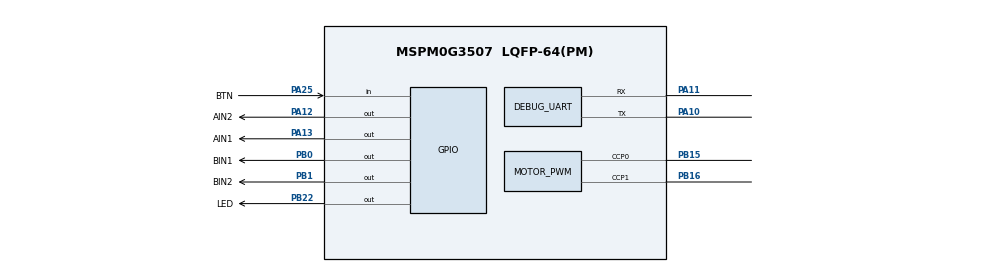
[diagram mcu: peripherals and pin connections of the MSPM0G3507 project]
/**
 * MSPM0G3507 PID Tuner Car
 *
 * PA25: start/stop key, active low
 * UART0: PA10=TX, PA11=RX, 115200 8N1 for PC PID tuner
 * TB6612FNG:
 *   A channel = right wheel: PWMA=PB15/TIMG8_C0, AIN1=PA13, AIN2=PA12
 *   B channel = left wheel:  PWMB=PB16/TIMG8_C1, BIN1=PB0,  BIN2=PB1
 * Encoders:
 *   Right A phase = PA15 edge interrupt
 *   Left  A phase = PA17 edge interrupt
 */
//@cliArgs --device "MSPM0G350X" --package "LQFP-64(PM)" --part "Default"
//@v2CliArgs --device "MSPM0G3507" --package "LQFP-64(PM)"

const GPIO   = scripting.addModule("/ti/driverlib/GPIO", {}, false);
const SYSCTL = scripting.addModule("/ti/driverlib/SYSCTL");
const UART   = scripting.addModule("/ti/driverlib/UART", {}, false);
const PWM    = scripting.addModule("/ti/driverlib/PWM", {}, false);
const Board  = scripting.addModule("/ti/driverlib/Board", {}, false);

const GPIO_LED   = GPIO.addInstance();
const GPIO_START = GPIO.addInstance();
const GPIO_DIR_A = GPIO.addInstance();
const GPIO_DIR_B = GPIO.addInstance();
const DEBUG_UART = UART.addInstance();
const MOTOR_PWM  = PWM.addInstance();

SYSCTL.forceDefaultClkConfig = true;

GPIO_LED.$name                         = "GPIO";
GPIO_LED.associatedPins[0].$name       = "LED";
GPIO_LED.associatedPins[0].pin.$assign = "PB22";

GPIO_START.$name                         = "START";
GPIO_START.associatedPins[0].$name       = "BTN";
GPIO_START.associatedPins[0].pin.$assign = "PA25";
GPIO_START.associatedPins[0].direction   = "INPUT";

GPIO_DIR_A.$name                         = "DIR_A";
GPIO_DIR_A.associatedPins.create(2);
GPIO_DIR_A.associatedPins[0].$name       = "AIN1";
GPIO_DIR_A.associatedPins[0].pin.$assign = "PA13";
GPIO_DIR_A.associatedPins[1].$name       = "AIN2";
GPIO_DIR_A.associatedPins[1].pin.$assign = "PA12";

GPIO_DIR_B.$name                         = "DIR_B";
GPIO_DIR_B.associatedPins.create(2);
GPIO_DIR_B.associatedPins[0].$name       = "BIN1";
GPIO_DIR_B.associatedPins[0].pin.$assign = "PB0";
GPIO_DIR_B.associatedPins[1].$name       = "BIN2";
GPIO_DIR_B.associatedPins[1].pin.$assign = "PB1";

DEBUG_UART.$name                           = "DEBUG_UART";
DEBUG_UART.targetBaudRate                  = 115200;
DEBUG_UART.enableFIFO                      = true;
DEBUG_UART.peripheral.rxPin.$assign        = "PA11";
DEBUG_UART.peripheral.txPin.$assign        = "PA10";
DEBUG_UART.txPinConfig.$name               = "ti_driverlib_gpio_GPIOPinGeneric0";
DEBUG_UART.txPinConfig.direction           = scripting.forceWrite("OUTPUT");
DEBUG_UART.txPinConfig.hideOutputInversion = scripting.forceWrite(false);
DEBUG_UART.txPinConfig.onlyInternalResistor = scripting.forceWrite(false);
DEBUG_UART.txPinConfig.passedPeripheralType = scripting.forceWrite("Digital");
DEBUG_UART.rxPinConfig.$name               = "ti_driverlib_gpio_GPIOPinGeneric1";
DEBUG_UART.rxPinConfig.hideOutputInversion = scripting.forceWrite(false);
DEBUG_UART.rxPinConfig.onlyInternalResistor = scripting.forceWrite(false);
DEBUG_UART.rxPinConfig.passedPeripheralType = scripting.forceWrite("Digital");

MOTOR_PWM.$name                         = "MOTOR_PWM";
MOTOR_PWM.timerStartTimer               = true;
MOTOR_PWM.timerCount                    = 2133;
MOTOR_PWM.clockPrescale                 = 1;
MOTOR_PWM.peripheral.ccp0Pin.$assign    = "PB15";
MOTOR_PWM.peripheral.ccp1Pin.$assign    = "PB16";
MOTOR_PWM.PWM_CHANNEL_0.$name           = "ti_driverlib_pwm_PWMTimerCC0";
MOTOR_PWM.PWM_CHANNEL_1.$name           = "ti_driverlib_pwm_PWMTimerCC1";

Board.peripheral.$suggestSolution          = "DEBUGSS";
Board.peripheral.swclkPin.$suggestSolution = "PA20";
Board.peripheral.swdioPin.$suggestSolution = "PA19";
SYSCTL.peripheral.$suggestSolution         = "SYSCTL";
DEBUG_UART.peripheral.$suggestSolution     = "UART0";
MOTOR_PWM.peripheral.$suggestSolution      = "TIMG8";
